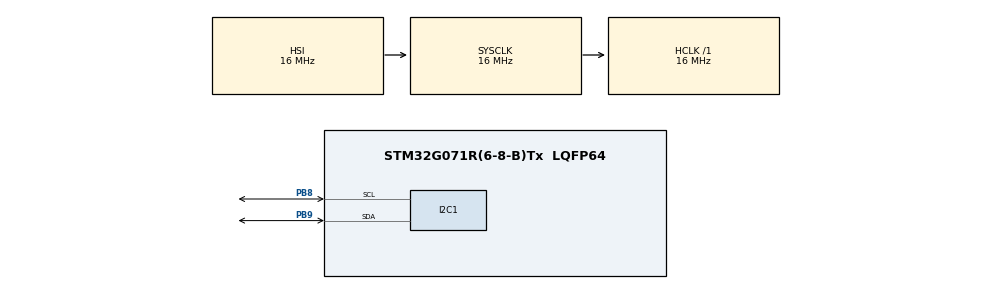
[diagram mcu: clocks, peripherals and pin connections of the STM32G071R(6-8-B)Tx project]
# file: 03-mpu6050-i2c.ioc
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I2C1.Timing=0x00503D58
Mcu.Family=STM32G0
Mcu.Name=STM32G071R(6-8-B)Tx
Mcu.Package=LQFP64
PB8.Mode=I2C
PB8.Signal=I2C1_SCL
PB9.Mode=I2C
PB9.Signal=I2C1_SDA
ProjectManager.HeapSize=0x200
ProjectManager.StackSize=0x400
ProjectManager.TargetToolchain=STM32CubeIDE
RCC.AHBFreq_Value=16000000
RCC.CortexFreq_Value=16000000
RCC.EXTERNAL_CLOCK_VALUE=48000
RCC.HCLKFreq_Value=16000000
RCC.HSE_VALUE=8000000
RCC.HSI_VALUE=16000000
RCC.LSE_VALUE=32768
RCC.SYSCLKFreq_VALUE=16000000
RCC.VCOOutputFreq_Value=128000000
board=custom

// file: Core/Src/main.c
/* USER CODE BEGIN Header */
/**
  ******************************************************************************
  * @file           : main.c
  * @brief          : Main program body
  ******************************************************************************
  * @attention
  *
  * Copyright (c) 2026 STMicroelectronics.
  * All rights reserved.
  *
  * This software is licensed under terms that can be found in the LICENSE file
  * in the root directory of this software component.
  * If no LICENSE file comes with this software, it is provided AS-IS.
  *
  ******************************************************************************
  */
/* USER CODE END Header */
#include "main.h"

/* USER CODE BEGIN Includes */
#include "uart_baremetal.h"
/* USER CODE END Includes */

/* USER CODE BEGIN PD */
/* USER CODE BEGIN PD */
#define MPU6050_ADDR (0x68 << 1)
#define PWR_MGMT_1   0x6B
#define WHO_AM_I     0x75
#define ACCEL_XOUT_H 0x3B
#define CRASH_THRESHOLD_SQ 1073741824UL   // 3g squared
/* USER CODE END PD */
/* USER CODE END PD */

I2C_HandleTypeDef hi2c1;

void SystemClock_Config(void);
static void MX_GPIO_Init(void);
static void MX_I2C1_Init(void);

int main(void)
{

  /* MCU Configuration--------------------------------------------------------*/

  /* Reset of all peripherals, Initializes the Flash interface and the Systick. */
  HAL_Init();

  /* Configure the system clock */
  SystemClock_Config();

  /* Initialize all configured peripherals */
  MX_GPIO_Init();
  MX_I2C1_Init();
  /* USER CODE BEGIN 2 */
  uart_init();
  printf("HelmetLink MPU6050 I2C\r\n");

  uint8_t buf[6] = {0};
  HAL_StatusTypeDef status;

  // Wake up MPU6050
  uint8_t zero = 0;
  status = HAL_I2C_Mem_Write(&hi2c1, MPU6050_ADDR, PWR_MGMT_1,
                             I2C_MEMADD_SIZE_8BIT, &zero, 1, 100);
  printf("Wake-up status: %d (0=OK, 1=ERROR, 2=BUSY, 3=TIMEOUT)\r\n", status);

  // Read WHO_AM_I
  status = HAL_I2C_Mem_Read(&hi2c1, MPU6050_ADDR, WHO_AM_I,
                            I2C_MEMADD_SIZE_8BIT, buf, 1, 100);
  printf("WHO_AM_I status: %d, value: 0x%02X\r\n", status, buf[0]);

  if(status == HAL_OK && buf[0] == 0x68)
  {
      printf("MPU6050 OK\r\n");
  }
  else
  {
      printf("MPU6050 FAIL\r\n");
  }

  /* USER CODE END 2 */

  /* Infinite loop */
  while (1)
  {

    /* USER CODE BEGIN 3 */

	  int16_t ax, ay, az;
	  int32_t mag_sq;

	  // Read 6 bytes: AXH, AXL, AYH, AYL, AZH, AZL
	  status = HAL_I2C_Mem_Read(&hi2c1, MPU6050_ADDR, ACCEL_XOUT_H,
	                            I2C_MEMADD_SIZE_8BIT, buf, 6, 100);

	  if(status == HAL_OK)
	  {
	      ax = (int16_t)((buf[0] << 8) | buf[1]);
	      ay = (int16_t)((buf[2] << 8) | buf[3]);
	      az = (int16_t)((buf[4] << 8) | buf[5]);

	      mag_sq = ((int32_t)ax * ax) + ((int32_t)ay * ay) + ((int32_t)az * az);

	      // Print values
	      printf("AX=%6d AY=%6d AZ=%6d MAG2=%10ld\r\n", ax, ay, az, mag_sq);

	      // Check crash
	      if(mag_sq > CRASH_THRESHOLD_SQ)
	      {
	          printf("CRASH DETECTED\r\n");
	          delay(500000);  // Cooldown ~500ms
	      }
	  }
	  else
	  {
	      printf("Accel read failed: %d\r\n", status);
	  }

	  // LED heartbeat
	  gpioa_odr ^= (1U << 5);
	  delay(500000);

  /* USER CODE END 3 */
}
}
void SystemClock_Config(void)
{
  RCC_OscInitTypeDef RCC_OscInitStruct = {0};
  RCC_ClkInitTypeDef RCC_ClkInitStruct = {0};

  /** Configure the main internal regulator output voltage
  */
  HAL_PWREx_ControlVoltageScaling(PWR_REGULATOR_VOLTAGE_SCALE1);

  /** Initializes the RCC Oscillators according to the specified parameters
  * in the RCC_OscInitTypeDef structure.
  */
  RCC_OscInitStruct.OscillatorType = RCC_OSCILLATORTYPE_HSI;
  RCC_OscInitStruct.HSIState = RCC_HSI_ON;
  RCC_OscInitStruct.HSIDiv = RCC_HSI_DIV1;
  RCC_OscInitStruct.HSICalibrationValue = RCC_HSICALIBRATION_DEFAULT;
  RCC_OscInitStruct.PLL.PLLState = RCC_PLL_NONE;
  if (HAL_RCC_OscConfig(&RCC_OscInitStruct) != HAL_OK)
  {
    Error_Handler();
  }

  /** Initializes the CPU, AHB and APB buses clocks
  */
  RCC_ClkInitStruct.ClockType = RCC_CLOCKTYPE_HCLK|RCC_CLOCKTYPE_SYSCLK
                              |RCC_CLOCKTYPE_PCLK1;
  RCC_ClkInitStruct.SYSCLKSource = RCC_SYSCLKSOURCE_HSI;
  RCC_ClkInitStruct.AHBCLKDivider = RCC_SYSCLK_DIV1;
  RCC_ClkInitStruct.APB1CLKDivider = RCC_HCLK_DIV1;

  if (HAL_RCC_ClockConfig(&RCC_ClkInitStruct, FLASH_LATENCY_0) != HAL_OK)
  {
    Error_Handler();
  }
}

static void MX_I2C1_Init(void)
{

  hi2c1.Instance = I2C1;
  hi2c1.Init.Timing = 0x00503D58;
  hi2c1.Init.OwnAddress1 = 0;
  hi2c1.Init.AddressingMode = I2C_ADDRESSINGMODE_7BIT;
  hi2c1.Init.DualAddressMode = I2C_DUALADDRESS_DISABLE;
  hi2c1.Init.OwnAddress2 = 0;
  hi2c1.Init.OwnAddress2Masks = I2C_OA2_NOMASK;
  hi2c1.Init.GeneralCallMode = I2C_GENERALCALL_DISABLE;
  hi2c1.Init.NoStretchMode = I2C_NOSTRETCH_DISABLE;
  if (HAL_I2C_Init(&hi2c1) != HAL_OK)
  {
    Error_Handler();
  }

  /** Configure Analogue filter
  */
  if (HAL_I2CEx_ConfigAnalogFilter(&hi2c1, I2C_ANALOGFILTER_ENABLE) != HAL_OK)
  {
    Error_Handler();
  }

  /** Configure Digital filter
  */
  if (HAL_I2CEx_ConfigDigitalFilter(&hi2c1, 0) != HAL_OK)
  {
    Error_Handler();
  }

}

static void MX_GPIO_Init(void)
{

  /* GPIO Ports Clock Enable */
  __HAL_RCC_GPIOB_CLK_ENABLE();

}

void Error_Handler(void)
{
  __disable_irq();
  while (1)
  {
  }
}
